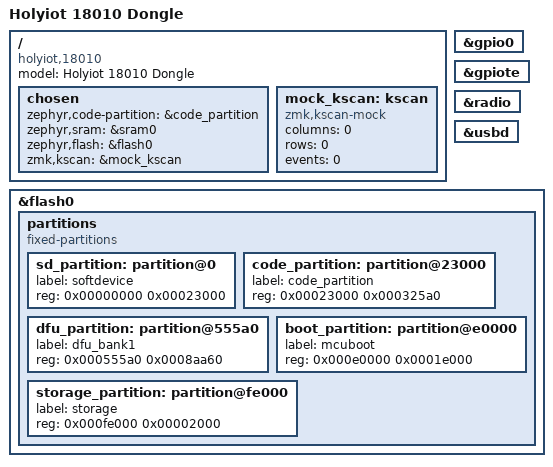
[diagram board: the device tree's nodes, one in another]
/dts-v1/;
#include <nordic/nrf52840_qiaa.dtsi>

/ {
    model = "Holyiot 18010 Dongle";
    compatible = "holyiot,18010";

    chosen {
        zephyr,code-partition = &code_partition;
        zephyr,sram = &sram0;
        zephyr,flash = &flash0;
        zmk,kscan = &mock_kscan;
    };

    mock_kscan: kscan {
        compatible = "zmk,kscan-mock";
        columns = <0>;
        rows = <0>;
        events = <0>;
    };
};

&gpio0 {
    status = "okay";
};

&gpiote {
    status = "okay";
};

&radio {
    status = "okay";
};

zephyr_udc0: &usbd {
    status = "okay";
};

&flash0 {
    partitions {
        compatible = "fixed-partitions";
        #address-cells = <1>;
        #size-cells = <1>;

        sd_partition: partition@0 {
            label = "softdevice";
            reg = <0x00000000 0x00023000>;
        };

        /* Application 영역 (201.4KB) */
        code_partition: partition@23000 {
            label = "code_partition";
            reg = <0x00023000 0x000325a0>;
        };

        dfu_partition: partition@555a0 {
            label = "dfu_bank1";
            reg = <0x000555a0 0x0008aa60>;
        };

        boot_partition: partition@e0000 {
            label = "mcuboot";
            reg = <0x000e0000 0x0001e000>;
        };

        storage_partition: partition@fe000 {
            label = "storage";
            reg = <0x000fe000 0x00002000>;
        };
    };
};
